# EMIF register map
Vendor: Texas Instruments
Peripheral module from a debugger description file (folder 66AK2G0x_66AK2G1x).
Registers are 32-bit, access per field, reset 0x0 unless marked. A register's access mark holds for its fields unless they carry their own. Offsets are as the file gives them; lines under a group give offsets from that group; [hi:lo] are bit positions; {n}, {i} and the like mark numbered series; 'fields as' and 'values as' point back to an identical list; <NAME> marks a mode.

## EMIF
0x00 EMIF_MIDR ro reset 0x40461C02
  [31:0] REV — TI internal data. Identifies revision of peripheral.
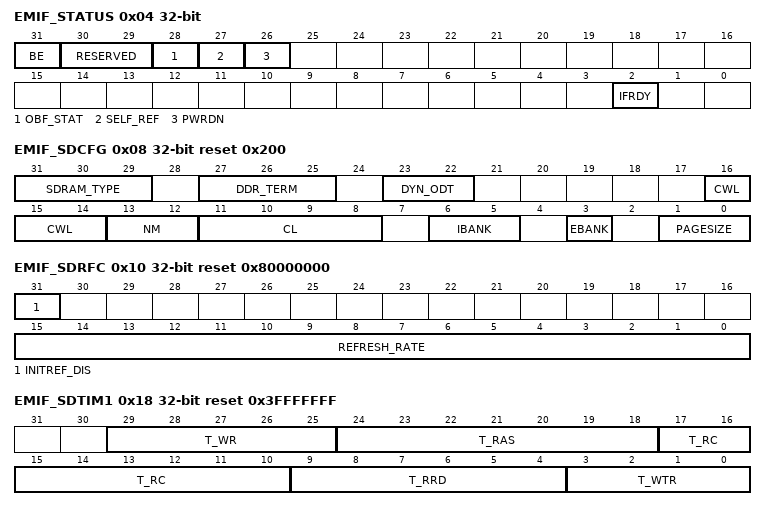
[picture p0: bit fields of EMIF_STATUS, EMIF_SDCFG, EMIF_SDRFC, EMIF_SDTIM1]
0x04 EMIF_STATUS ro
  [31] BE — Indicates whether the EMIF is in big or little-endian mode.NOTE: Only little-endian mode is supported on this device.
  [30:29] RESERVED — This field is tied off to 1h.
  [28] OBF_STAT — Obfuscation Status.
  [27] SELF_REF — Self refresh mode status.
  [26] PWRDN — Power down status.
  [2] IFRDY — EMIF controller interface logic ready bit. The interface logic controls the signals used to communicate with DDR3 SDRAM devices. This bit displays the status of the interface logic.
0x08 EMIF_SDCFG reset 0x200
  [31:29] SDRAM_TYPE rw — SDRAM type selection. Set to 3 for DDR3. All other values reserved.
  [27:25] DDR_TERM rw — Defines termination resistor value.
  [23:22] DYN_ODT rw — Dynamic On-Die Termination All other values reserved.
  [16:14] CWL rw — CAS Write Latency. Lower value gives better performance.
  [13:12] NM rw — DDR3 data bus width. All other values reserved.
  [11:8] CL rw — CAS Latency. The value of this field defines the CAS latency, to be used when accessing connected SDRAM devices. All other values are reserved.
  [6:5] IBANK rw — Internal SDRAM bank setup bits. Defines number of banks inside connected SDRAM devices. Values 4-7 are reserved for this field. A word is equal to the bus width of the individual SDRAM devices used (example, 1 byte for x8 and 2bytes for x16 devices)
  [3] EBANK rw — External chip select setup. Defines whether SDRAM accesses use 1 or 2 chip select lines as follows:
  [1:0] PAGESIZE rw — Page size bits. Defines internal page size of the external DDR3 memory. Values 4-7 are reserved for this field. A word is equal to the bus width of the individual SDRAM devices used (example, 1 byte for x8 and 2 bytes for x16 devices)
0x10 EMIF_SDRFC reset 0x80000000
  [31] INITREF_DIS rw — Refresh Disable.
  [15:0] REFRESH_RATE rw — The value in this field is used to define the rate at which connected SDRAM devices will be refreshed.REFRESH_RATE = Refresh period * DDR3 clock frequency.
0x18 EMIF_SDTIM1 reset 0x3FFFFFFF
  [29:25] T_WR rw — These bits specify the minimum number of DDR3_CLKOUT cycles from the last write transfer to a precharge command, minus 1. The value of this parameter can be derived from the t AC timing parameter in the DDR3 memory data sheet. Calculate using the formula: T_WR = (t
  [24:18] T_RAS rw — These bits specify the minimum number of DDR3_CLKOUT cycles from an activate command to precharge command, minus 1. The value of this parameter can be derived from the minimum value of the t AC timing parameter in the DDR3 memory data sheet. Calculate using the formula: T_RAS = (t
  [17:10] T_RC rw — These bits specify the minimum number of DDR3_CLKOUT cycles from an activate command to an activate command, minus 1. The value of this parameter can be derived from the tAC timing parameter in the DDR3 memory data sheet. Calculate using the formula: T_RC = (t
  [9:4] T_RRD rw — These bits specify the minimum number of DDR3_CLKOUT cycles from an activate to an activate in a different bank, minus 1. The value of this parameter can be derived from the t AC timing parameter in the DDR3 memory data sheet. Calculate using the formula: T_RRD = (t
  [3:0] T_WTR rw — These bits specify the minimum number of DDR3_CLKOUT cycles from the last write to a read command, minus 1. The value of this parameter can be derived from the t AC timing parameter in the DDR3 memory data sheet. Convert the t value from the memory data sheet into ns before using the formula below. Calculate using the formula: T_WTR = (t
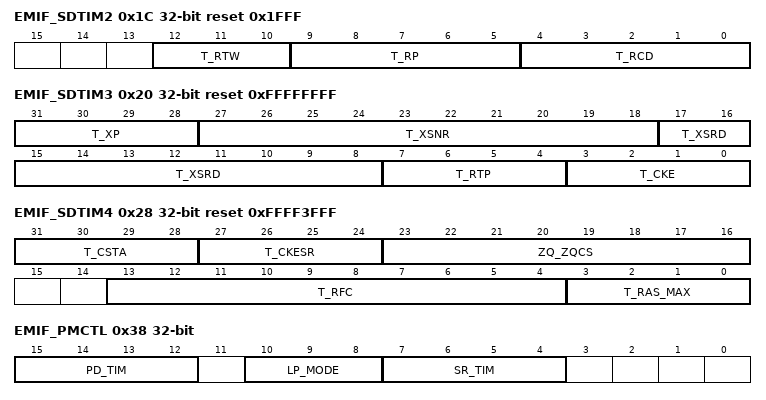
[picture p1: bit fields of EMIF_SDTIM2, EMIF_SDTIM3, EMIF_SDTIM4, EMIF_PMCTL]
0x1C EMIF_SDTIM2 reset 0x1FFF
  [12:10] T_RTW rw — Minimum number of DDR3_CLKOUT cycles between read and write date phases, minus 1. This is not an SDRAM timing parameter. The value depends on the board topology supported.For single rank: reg_t_RTW= (((2*dqs_delay_for_cs0)+tDQSCK+ wr_leveling_tolerance)/clock_period)-1 For dual rank: reg_t_RTW= ((dqs_delay_for_cs0+dqs_delay_for_cs1+ absolute(command_delay_for_cs0-command_delay_for_cs1)+tDQSCK+ wr_leveling_tolerance)/clock_period)-1
  [9:5] T_RP rw — These bits specify the minimum number of DDR3_CLKOUT cycles from a precharge command to a refresh or activate command, minus 1. The value of this parameter can be derived from the t AC timing parameter in the DDR3 memory data sheet. Calculate using the formula: T_RP = (t
  [4:0] T_RCD rw — These bits specify the minimum number of DDR3_CLKOUT cycles from an activate command to a read or write command, minus 1. The value of this parameter can be derived from the t AC timing parameter in the DDR3 memory data sheet. Calculate using the formula: T_RCD = (t
0x20 EMIF_SDTIM3 rw reset 0xFFFFFFFF
  [31:28] T_XP — These bits specify the minimum number of DDR3_CLKOUT cycles from Power down exit to any command other than a read command, minus 1. The value of this parameter can be derived from the t AC timing parameter in the DDR3 memory data sheet. Convert the t data sheet parameter value into ns before using the formula below. Calculate using the formula: T_XP = (t
  [27:18] T_XSNR — These bits specify the minimum number of DDR3_CLKOUT cycles from a self-refresh exit to a command that does not require a locked DLL, minus 1. The value of this parameter can be derived from the t AC timing parameter in the DDR3 memory data sheet. Calculate using the formula: T_XSNR = (t
  [17:8] T_XSRD — These bits specify the minimum number of DDR3_CLKOUT cycles from a self-refresh exit to a command that requires a locked DLL, minus 1. The value of this parameter can be derived from the tAC timing parameter in the DDR3 memory data sheet. This parameter typically appears in the data sheet in terms of t clock cycles. Calculate using the formula: T_XSRD = t
  [7:4] T_RTP — These bits specify the minimum number of DDR3_CLKOUT cycles from the last read to precharge command, minus 1. The value of this parameter can be derived from the t AC timing parameter in the DDR3 memory data sheet. Convert the t data sheet parameter value into ns before using formula below. Calculate using the formula: T_RTP = (t
  [3:0] T_CKE — These bits specify the minimum number of DDR3_CLKOUT cycles between transitions on the DDR3_CKE pin, minus 1. The value of this parameter can be derived from the t AC timing parameter in the DDR3 memory data sheet. Calculate using the formula: T_CKE = (t
0x28 EMIF_SDTIM4 reset 0xFFFF3FFF
  [31:28] T_CSTA rw — Minimum DDR3_CLKOUT cycles between write-to-write or read-to-read data phases to different chip selects, minus 1.
  [27:24] T_CKESR rw — Value = 0Minimum DDR3_CLKOUT cycles for which DDR3 should remain in self-refresh. This parameter typically appears as number of t T_CKESR = (t
  [23:16] ZQ_ZQCS rw — These bits specify the minimum number of DDR3_CLKOUT cycles for a ZQCS command, minus 1. The value of this parameter can be derived from the t AC timing parameter in the DDR3 memory data sheet. This parameter typically appears as number of t clock cycles. Calculate using the formula : ZQ_ZQCS = t
  [13:4] T_RFC rw — These bits specify the minimum number of DDR3_CLKOUT cycles from a refresh or load mode command to a refresh or activate command, minus 1. The value of this parameter can be derived from the t AC timing parameter in the DDR3 memory data sheet. Calculate using the formula: T_RFC = (t
  [3:0] T_RAS_MAX rw — This field must always be programmed to Fh.
0x38 EMIF_PMCTL
  [15:12] PD_TIM rw — Power Management timer for power-down. The EMIF controller puts the SDRAM in power-down mode after the EMIF controller is idle for PD_TIM number of DDR3_CLKOUT cycles and if LP_MODE is set to 4.
  [10:8] LP_MODE rw — Automatic power management enable. All other values disable automatic power management.
  [7:4] SR_TIM rw — Power management timer for self-refresh. The EMIF controller will put the external SDRAM in self-refresh mode after EMIF controller has been idle for these number of DDR3_CLKOUT cycles and LP_MODE is set to 2.
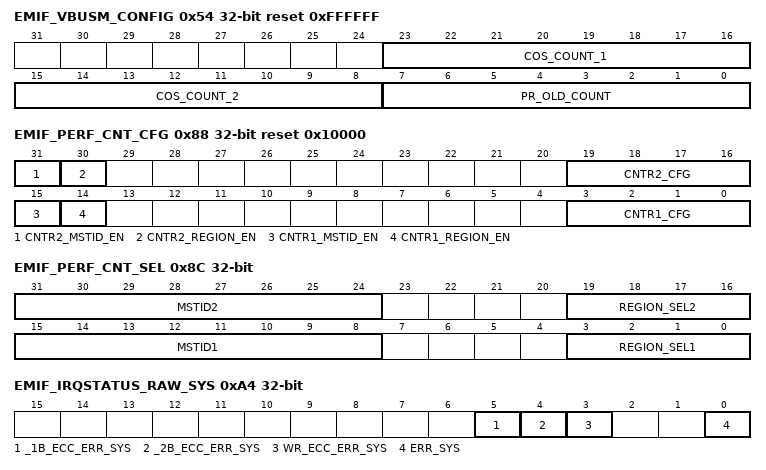
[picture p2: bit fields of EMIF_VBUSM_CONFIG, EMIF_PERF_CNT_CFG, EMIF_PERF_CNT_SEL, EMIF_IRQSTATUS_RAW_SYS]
0x54 EMIF_VBUSM_CONFIG reset 0xFFFFFF
  [23:16] COS_COUNT_1 rw — Priority raise counter for Class of Service 1. Number of DDR3_CLKOUT cycles after which the EMIF controller momentarily raises the priority of Class of Service 1 commands in Command FIFO. Number of clock cycles = COS_COUNT_1 x 16 clocks
  [15:8] COS_COUNT_2 rw — Priority raise counter for Class of Service 2. Number of DDR3_CLKOUT cycles after which the EMIF controller momentarily raises the priority of Class of Service 2 commands in Command FIFO. Number of clock cycles = COS_COUNT_2 x 16 clocks
  [7:0] PR_OLD_COUNT rw — Priority raise old counter. Number of DDR3_CLKOUT cycles after which EMIF controller momentarily raises the priority of the oldest command in Command FIFO. Number of clock cycles = PR_OLD_COUNT_2 x 16 clocks
0x80 EMIF_PERF_CNT_1 ro
  [31:0] COUNTER_1 — 32-bit counter can be programmed as specified in the Performance Counter Config and Performance Counter Master Region Select registers.
0x84 EMIF_PERF_CNT_2 ro
  [31:0] COUNTER_2 — 32-bit counter can be programmed as specified in the Performance Counter Config and Performance Counter Master Region Select registers.
0x88 EMIF_PERF_CNT_CFG reset 0x10000
  [31] CNTR2_MSTID_EN rw — Master ID filter enable for Performance Counter 2 Register. Set to 1 to enable filtering of events for counter 2 by Master ID.
  [30] CNTR2_REGION_EN rw — Memory space region enable for Performance Counter 2 Register. Set to 1 to enable filtering of events for counter 2 by the accessed memory region.
  [19:16] CNTR2_CFG rw — Filter configuration selected for Performance Counter 2. This field selects the type of event to count for Counter 2. Refer to for various configuration options.
  [15] CNTR1_MSTID_EN rw — Master ID filter enable for Performance Counter 1 Register. Set to 1 to enable filtering of events for counter 1 by Master ID.
  [14] CNTR1_REGION_EN rw — Memory space region enable for Performance Counter 1 Register. Set to 1 to enable filtering of events for counter 1 by the accessed memory region.
  [3:0] CNTR1_CFG rw — Filter configuration selected for Performance Counter 1. This field selects the type of event to count for Counter 1. Refer to for various configuration options.
0x8C EMIF_PERF_CNT_SEL
  [31:24] MSTID2 rw — Master ID for Performance Counter 2 Register.
  [19:16] REGION_SEL2 rw — Region select for Performance Counter 2. All other values are reserved.
  [15:8] MSTID1 rw — Master ID for Performance Counter 1 Register.
  [3:0] REGION_SEL1 rw — Region select for Performance Counter 1. All other values are reserved.
0x90 EMIF_PERF_CNT_TIM ro
  [31:0] TOTAL_TIME — 32-bit counter continuously counts number of DDR/2 clock cycles elapsed after the controller is brought out of reset.
0xA4 EMIF_IRQSTATUS_RAW_SYS access not given
  [5] _1B_ECC_ERR_SYS — Value = 0hRaw status of 1-bit ECC error interrupt. Writing a 1 sets the raw status. Writing a 0 has no effect. (access WOS)
  [4] _2B_ECC_ERR_SYS — Value = 0hRaw status of 2-bit ECC error interrupt. Writing a 1 sets the raw status. Writing a 0 has no effect. (access WOS)
  [3] WR_ECC_ERR_SYS — Value = 0hRaw status of write ECC error interrupt. Writing a 1 sets the raw status. Writing a 0 has no effect. (access WOS)
  [0] ERR_SYS — Value = 0hRaw status of system VBUSM interrupt for command or address error. Writing a 1 sets the raw status. Writing a 0 has no effect. (access WOS)
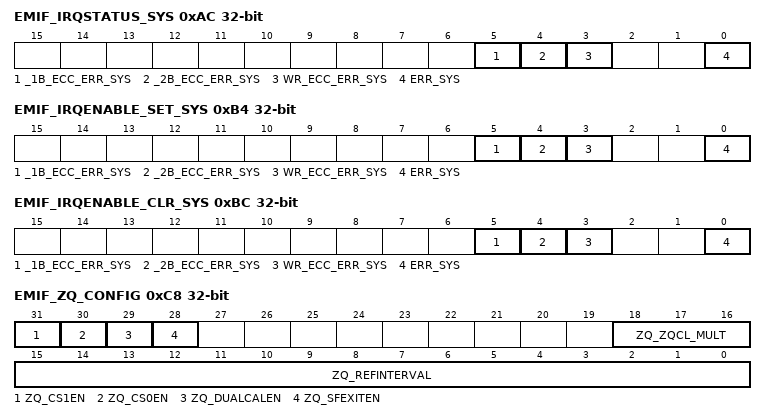
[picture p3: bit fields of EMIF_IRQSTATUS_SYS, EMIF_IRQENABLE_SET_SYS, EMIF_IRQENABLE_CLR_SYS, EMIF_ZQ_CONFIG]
0xAC EMIF_IRQSTATUS_SYS access not given
  [5] _1B_ECC_ERR_SYS — Value = 0hEnabled status of 1-bit ECC error interrupt. Writing a 1 clears the status as well the raw status. Writing a 0 has no effect. (access WOC)
  [4] _2B_ECC_ERR_SYS — Value = 0hEnabled status of 2-bit ECC error interrupt. Writing a 1 clears the status as well the raw status. Writing a 0 has no effect. (access WOC)
  [3] WR_ECC_ERR_SYS — Value = 0hEnabled status of write ECC error interrupt. Writing a 1 clears the status as well the raw status. Writing a 0 has no effect. (access WOC)
  [0] ERR_SYS — Value = 0hEnabled status of system VBUSM interrupt for command or address error. Writing a 1 clears the status as well the raw status. Writing a 0 has no effect. (access WOC)
0xB4 EMIF_IRQENABLE_SET_SYS access not given
  [5] _1B_ECC_ERR_SYS — Value = 0hEnabled set for 1-bit ECC error interrupt. Writing a 1 will enable the read ECC error interrupt, set this bit as well as the bit in Interrupt Enable Clear Register. Writing a 0 has no effect. (access WOS)
  [4] _2B_ECC_ERR_SYS — Value = 0hEnabled set for 2-bit ECC error interrupt. Writing a 1 will enable the read ECC error interrupt, set this bit as well as the bit in Interrupt Enable Clear Register. Writing a 0 has no effect. (access WOS)
  [3] WR_ECC_ERR_SYS — Value = 0hEnabled set for write ECC error interrupt. Writing a 1 will enable the write ECC error interrupt, set this bit as well as the bit in Interrupt Enable Clear Register. Writing a 0 has no effect. (access WOS)
  [0] ERR_SYS — Value = 0hEnable set for system VBUSM interrupt for command or address error. Writing a 1 will enable the interrupt, and set this bit as well as the corresponding Interrupt Enable Clear Register. Writing a 0 has no effect. (access WOS)
0xBC EMIF_IRQENABLE_CLR_SYS access not given
  [5] _1B_ECC_ERR_SYS — Value = 0hEnabled clear for 1-bit ECC error interrupt. Writing a 1 will disable the read ECC error interrupt, clear this bit as well as the bit in Interrupt Enable Clear Register. Writing a 0 has no effect. (access WOC)
  [4] _2B_ECC_ERR_SYS — Value = 0hEnabled clear for 2-bit ECC error interrupt. Writing a 1 will disable the read ECC error interrupt, clear this bit as well as the bit in Interrupt Enable Clear Register. Writing a 0 has no effect. (access WOC)
  [3] WR_ECC_ERR_SYS — Value = 0hEnabled clear for write ECC error interrupt. Writing a 1 will disable the write ECC error interrupt, clear this bit as well as the bit in Interrupt Enable Clear Register. Writing a 0 has no effect. (access WOC)
  [0] ERR_SYS — Value = 0hEnable clear for system VBUSM interrupt for command or address error. Writing a 1 will disable the interrupt, and clear this bit as well as the corresponding Interrupt Enable Set Register. Writing a 0 has no effect. (access WOC)
0xC8 EMIF_ZQ_CONFIG
  [31] ZQ_CS1EN rw — ZQ calibration for CS1
  [30] ZQ_CS0EN rw — ZQ calibration for CS0
  [29] ZQ_DUALCALEN rw — ZQ Dual Calibration enable. Allows both ranks to be calibrated simultaneously.
  [28] ZQ_SFEXITEN rw — ZQCL on Self-refresh, Active power-down and precharge power-down exit enable.Set this value to 1 to issue a ZQCL command upon self-refresh exit.
  [18:16] ZQ_ZQCL_MULT rw — Number of ZQCS intervals that make up a ZQCL interval, minus one. ZQCS interval is defined by theEMIF_SDTIM4[23-16] ZQ_ZQCS field. The value of this parameter can be derived using the formula: T_ZQ_ZQCL_MULT = (t
  [15:0] ZQ_REFINTERVAL rw — Number of refresh periods between ZQCS commands, minus one. This field supports between one refresh period to 256 ms between ZQCS calibration commands. Refresh period is defined by theEMIF_SDRFC[15-0] REFRESH_RATE field. ZQ_REFINTERVAL = number of refresh periods between ZQCS commands. The interval is calculated as = 0.5% / [(Tsens x Tdriftrate) + (Vsens x Vdriftrate)]. Tsens = max (dRTTdT, dRONdTM) from the memory device data sheet. Vsens = max(dRTTdV, dRONdVM) from the memory device data sheet Tdriftrate = drift rate in Example: If Tsens= 1.5%/ Interval = 0.5/[(1.5 x 1.2) + (0.15 x 10)] = 152ms. Since refresh interval = 7.8µs, ZQ_REFINTERVAL = 152ms/7.8µs = 4C1Fh
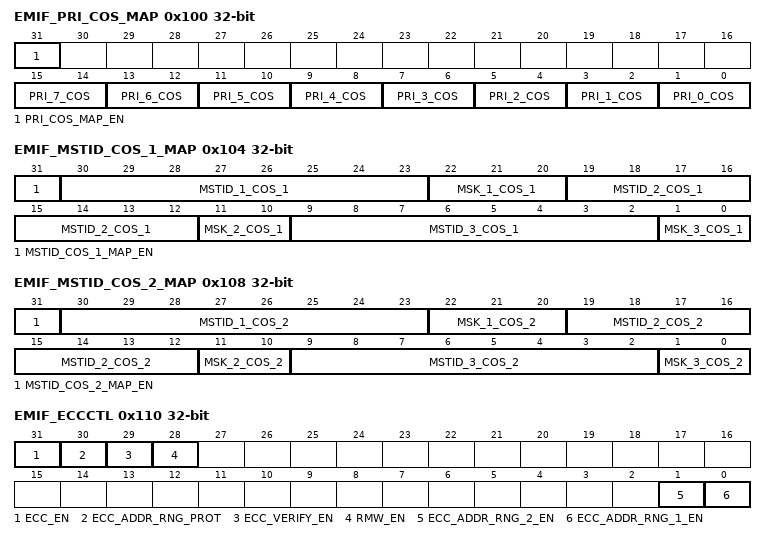
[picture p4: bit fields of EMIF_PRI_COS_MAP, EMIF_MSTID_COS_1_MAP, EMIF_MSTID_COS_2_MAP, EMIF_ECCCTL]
0x100 EMIF_PRI_COS_MAP
  [31] PRI_COS_MAP_EN rw — Priority to Class-of-service mapping
  [15:14] PRI_7_COS rw — Class-of-service for commands with priority of 7 (lowest priority).
  [2n+1:2n] PRI_{n}_COS rw (n=1..6) — Class-of-service for commands with priority of {n}.
  [1:0] PRI_0_COS rw — Class-of-service for commands with priority of 0 (highest priority).
0x104 EMIF_MSTID_COS_1_MAP rw
  [31] MSTID_COS_1_MAP_EN — Master ID to Class-of-service 1 mapping.
  [30:23] MSTID_1_COS_1 — Master ID value 1 for Class-of-service 1.
  [22:20] MSK_1_COS_1 — Mask for master ID value 1 for Class-of-service 1.
  [19:12] MSTID_2_COS_1 — Master ID value 2 for Class-of-service 1.
  [11:10] MSK_2_COS_1 — Mask for master ID value 2 for Class-of-service 1.
  [9:2] MSTID_3_COS_1 — Master ID value 3 for Class-of-service 1.
  [1:0] MSK_3_COS_1 — Mask for master ID value 3 for Class-of-service 1.
0x108 EMIF_MSTID_COS_2_MAP rw
  [31] MSTID_COS_2_MAP_EN — Master ID to Class-of-service 2 mapping.
  [30:23] MSTID_1_COS_2 — Master ID value 1 for Class-of-service 2.
  [22:20] MSK_1_COS_2 — Mask for master ID value 1 for Class-of-service 2.
  [19:12] MSTID_2_COS_2 — Master ID value 2 for Class-of-service 2.
  [11:10] MSK_2_COS_2 — Mask for master ID value 2 for Class-of-service 2.
  [9:2] MSTID_3_COS_2 — Master ID value 3 for Class-of-service 2.
  [1:0] MSK_3_COS_2 — Mask for master ID value 3 for Class-of-service 2.
0x110 EMIF_ECCCTL
  [31] ECC_EN rw — ECC enable.
  [30] ECC_ADDR_RNG_PROT rw — This bit is used to determine whether ECC calculation is allowed within address ranges described by ECC Address Range 1 and 2 Registers, provided ECC_EN is set to enable ECC.
  [29] ECC_VERIFY_EN rw — This field is ignored if ECC_EN=0.
  [28] RMW_EN rw — This field is ignored if ECC_EN=0.
  [1] ECC_ADDR_RNG_2_EN rw — ECC Address Range 2 enable.
  [0] ECC_ADDR_RNG_1_EN rw — ECC Address Range 1 enable.
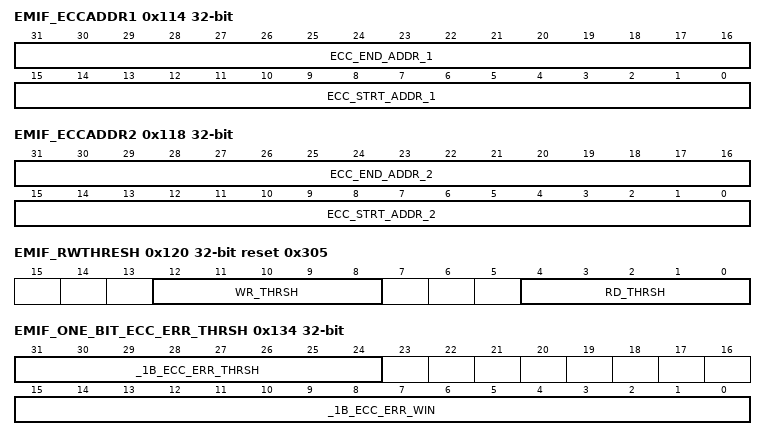
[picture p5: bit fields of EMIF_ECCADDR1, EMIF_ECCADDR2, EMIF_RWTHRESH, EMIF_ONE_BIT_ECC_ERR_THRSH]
0x114 EMIF_ECCADDR1 rw
  [31:16] ECC_END_ADDR_1 — End address [32-17] of 33-bit address for ECC address range 1. If this bit field is set to 1000h, this indicates that the SDRAM physical end address on which the ECC applies is 0_2001_FFFFh. If this bit field is set to 0FFFh the physical end address on which the ECC applies is 0_1FFF_FFFFh. This bit field controls only the 16 MSbs of the physical end address of the ECC protected range. The other 17 LSbs are always 1_FFFFh.
  [15:0] ECC_STRT_ADDR_1 — Start address [32-17] of 33-bit address for ECC address range 1. If this bit field is set to 0000h, this indicates that the SDRAM physical start address on which the ECC applies is 0_0000_0000h. This bit field controls only the 16 MSbs of the physical start address of the ECC protected range. The other 17 LSbs are always 0_0000h.
0x118 EMIF_ECCADDR2 rw
  [31:16] ECC_END_ADDR_2 — End address [32-17] of 33-bit address for ECC address range 2. If this bit field is set to 1000h, this indicates that the SDRAM physical end address on which the ECC applies is 0_2001_FFFFh. If this bit field is set to 0FFFh the physical end address on which the ECC applies is 0_1FFF_FFFFh. This bit field controls only the 16 MSbs of the physical end address of the ECC protected range. The other 17 LSbs are always 1_FFFFh.
  [15:0] ECC_STRT_ADDR_2 — Start address [32-17] of 33-bit address for ECC address range 2. If this bit field is set to 0000h, this indicates that the SDRAM physical start address on which the ECC applies is 0_0000_0000h. This bit field controls only the 16 MSbs of the physical start address of the ECC protected range. The other 17 LSbs are always 0_0000h.
0x120 EMIF_RWTHRESH reset 0x305
  [12:8] WR_THRSH rw — Write Threshold. Number of SDRAM write bursts after which the arbitration will switch to executing read commands. The value programmed is always minus 1 the required number.
  [4:0] RD_THRSH rw — Read Threshold. Number of SDRAM read bursts after which the arbitration will switch to executing write commands. The value programmed is always minus 1 the required number.
0x130 EMIF_ONE_BIT_ECC_ERR_CNT access not given
  [31:0] _1B_ECC_ERR_CNT — 32-bit counter that displays the number of 1-bit ECC errors. Writing a value will decrement the count by that value. (access WS)
0x134 EMIF_ONE_BIT_ECC_ERR_THRSH
  [31:24] _1B_ECC_ERR_THRSH rw — 1-bit ECC error threshold. The EMIF controller generates an interrupt when the 1-bit ECC error count is greater than this threshold. A value of 0 disables the generation of interrupt.
  [15:0] _1B_ECC_ERR_WIN rw — 1-bit ECC error window in number of refresh periods. The controller generates an interrupt when the 1-bit ECC error count is equal to or greater than the threshold within this window. A value of 0 disables the window. Refresh period is defined by the
0x138 EMIF_ONE_BIT_ECC_ERR_DIST_1 access not given
  [31:0] _1B_ECC_ERR_DST_1 — 1-bit ECC error distribution over data bus bits 31:0. A value of 1 on a bit indicates 1-bit error on the corresponding bit on the data bus. Writing a 1 to any bit clears that bit. Writing a 0 has no effect. (access WOC)
0x13C EMIF_ONE_BIT_ECC_ERR_ADDR_LOG rw
  [31:0] _1B_ECC_ERR_ADDR — 1-bit ECC error address. Most significant bits of the starting address of the first two SDRAM bursts that had the 1-bit ECC error. This field displays the first address logged in the 2 deep address logging FIFO. Writing a 1h will pop one element of the FIFO. Writing a 2h will pop both the elements of the FIFO.Writing any other value has no effect..
0x140 EMIF_TWO_BIT_ECC_ERR_ADDR_LOG rw
  [31:0] _2B_ECC_ERR_ADDR — 2-bit ECC error address. Most significant bits of the start address of the first SDRAM burst that had the 2-bit ECC error. Writing 1h clears this field. Writing any other value has no effect.
0x144 EMIF_ONE_BIT_ECC_ERR_DIST_2 access not given
  [31:0] _1B_ECC_ERR_DST_2 — 1-bit ECC error distribution over data bus bits 63:32. A value of 1 on a bit indicates 1-bit error on the corresponding bit on the data bus. Writing a 1 to any bit will clear that bit. Writing a 0 has no effect. (access WOC)
